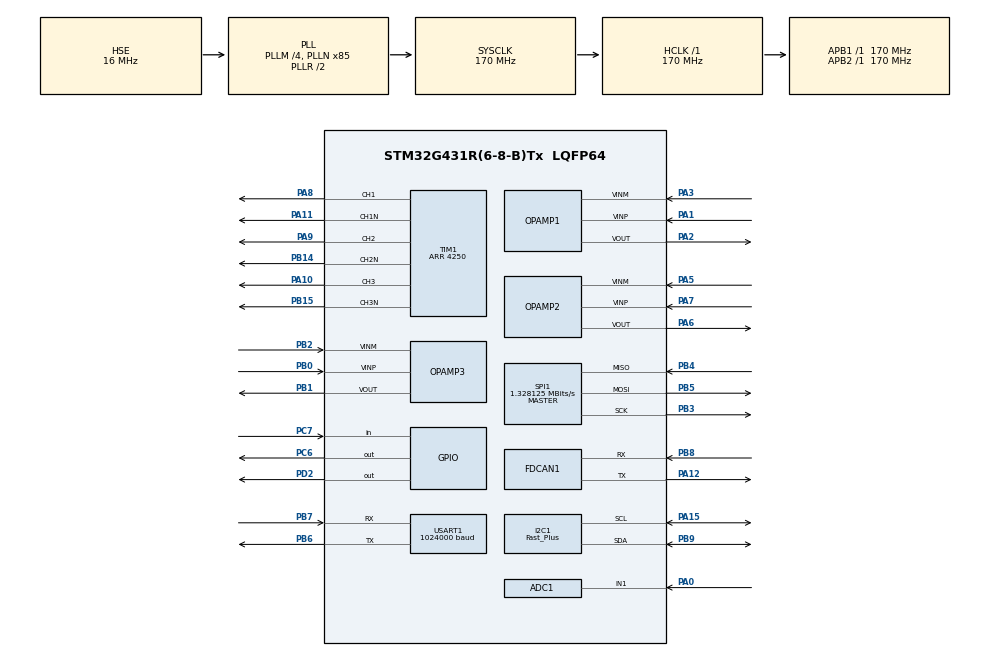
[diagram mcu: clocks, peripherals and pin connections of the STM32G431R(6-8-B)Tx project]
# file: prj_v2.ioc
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ADC1.Channel-0\#ChannelRegularConversion=ADC_CHANNEL_3
ADC1.Channel-1\#ChannelRegularConversion=ADC_CHANNEL_12
ADC1.ClockPrescaler=ADC_CLOCK_ASYNC_DIV2
ADC1.DMAContinuousRequests=ENABLE
ADC1.EOCSelection=ADC_EOC_SEQ_CONV
ADC1.ExternalTrigConv=ADC_EXTERNALTRIG_T1_TRGO
ADC1.NbrOfConversion=2
ADC1.NbrOfConversionFlag=1
ADC1.OffsetNumber-1\#ChannelRegularConversion=ADC_OFFSET_NONE
ADC1.Rank-1\#ChannelRegularConversion=2
ADC1.SamplingTime-0\#ChannelRegularConversion=ADC_SAMPLETIME_12CYCLES_5
ADC1.SamplingTime-1\#ChannelRegularConversion=ADC_SAMPLETIME_12CYCLES_5
ADC1.master=1
ADC2.Channel-0\#ChannelRegularConversion=ADC_CHANNEL_3
ADC2.ClockPrescaler=ADC_CLOCK_ASYNC_DIV2
ADC2.DMAContinuousRequests=ENABLE
ADC2.EOCSelection=ADC_EOC_SEQ_CONV
ADC2.EnableInjectedConversion=DISABLE
ADC2.ExternalTrigConv=ADC_EXTERNALTRIG_T1_TRGO
ADC2.NbrOfConversion=1
ADC2.NbrOfConversionFlag=1
ADC2.OffsetNumber-0\#ChannelRegularConversion=ADC_OFFSET_NONE
ADC2.Rank-0\#ChannelRegularConversion=1
ADC2.Rank1_Channel=ADC_CHANNEL_3
ADC2.SamplingTime-0\#ChannelRegularConversion=ADC_SAMPLETIME_12CYCLES_5
DAC1.DAC_Channel-DAC_OUT2_Int=DAC_CHANNEL_2
Dma.ADC1.2.Direction=DMA_PERIPH_TO_MEMORY
Dma.ADC1.2.EventEnable=DISABLE
Dma.ADC1.2.Instance=DMA1_Channel3
Dma.ADC1.2.MemDataAlignment=DMA_MDATAALIGN_HALFWORD
Dma.ADC1.2.MemInc=DMA_MINC_ENABLE
Dma.ADC1.2.Mode=DMA_CIRCULAR
Dma.ADC1.2.PeriphDataAlignment=DMA_PDATAALIGN_HALFWORD
Dma.ADC1.2.PeriphInc=DMA_PINC_DISABLE
Dma.ADC1.2.Polarity=HAL_DMAMUX_REQ_GEN_RISING
Dma.ADC1.2.Priority=DMA_PRIORITY_LOW
Dma.ADC1.2.RequestNumber=1
Dma.ADC1.2.SignalID=NONE
Dma.ADC1.2.SyncEnable=DISABLE
Dma.ADC1.2.SyncPolarity=HAL_DMAMUX_SYNC_NO_EVENT
Dma.ADC1.2.SyncRequestNumber=1
Dma.ADC1.2.SyncSignalID=NONE
Dma.ADC2.3.Direction=DMA_PERIPH_TO_MEMORY
Dma.ADC2.3.EventEnable=DISABLE
Dma.ADC2.3.Instance=DMA1_Channel4
Dma.ADC2.3.MemDataAlignment=DMA_MDATAALIGN_HALFWORD
Dma.ADC2.3.MemInc=DMA_MINC_ENABLE
Dma.ADC2.3.Mode=DMA_CIRCULAR
Dma.ADC2.3.PeriphDataAlignment=DMA_PDATAALIGN_HALFWORD
Dma.ADC2.3.PeriphInc=DMA_PINC_DISABLE
Dma.ADC2.3.Polarity=HAL_DMAMUX_REQ_GEN_RISING
Dma.ADC2.3.Priority=DMA_PRIORITY_LOW
Dma.ADC2.3.RequestNumber=1
Dma.ADC2.3.SignalID=NONE
Dma.ADC2.3.SyncEnable=DISABLE
Dma.ADC2.3.SyncPolarity=HAL_DMAMUX_SYNC_NO_EVENT
Dma.ADC2.3.SyncRequestNumber=1
Dma.ADC2.3.SyncSignalID=NONE
Dma.I2C1_RX.4.Direction=DMA_PERIPH_TO_MEMORY
Dma.I2C1_RX.4.EventEnable=DISABLE
Dma.I2C1_RX.4.Instance=DMA1_Channel5
Dma.I2C1_RX.4.MemDataAlignment=DMA_MDATAALIGN_BYTE
Dma.I2C1_RX.4.MemInc=DMA_MINC_ENABLE
Dma.I2C1_RX.4.Mode=DMA_NORMAL
Dma.I2C1_RX.4.PeriphDataAlignment=DMA_PDATAALIGN_BYTE
Dma.I2C1_RX.4.PeriphInc=DMA_PINC_DISABLE
Dma.I2C1_RX.4.Polarity=HAL_DMAMUX_REQ_GEN_RISING
Dma.I2C1_RX.4.Priority=DMA_PRIORITY_LOW
Dma.I2C1_RX.4.RequestNumber=1
Dma.I2C1_RX.4.SignalID=NONE
Dma.I2C1_RX.4.SyncEnable=DISABLE
Dma.I2C1_RX.4.SyncPolarity=HAL_DMAMUX_SYNC_NO_EVENT
Dma.I2C1_RX.4.SyncRequestNumber=1
Dma.I2C1_RX.4.SyncSignalID=NONE
Dma.Request0=USART1_TX
Dma.Request1=USART1_RX
Dma.Request2=ADC1
Dma.Request3=ADC2
Dma.Request4=I2C1_RX
Dma.USART1_RX.1.Direction=DMA_PERIPH_TO_MEMORY
Dma.USART1_RX.1.EventEnable=DISABLE
Dma.USART1_RX.1.Instance=DMA1_Channel2
Dma.USART1_RX.1.MemDataAlignment=DMA_MDATAALIGN_BYTE
Dma.USART1_RX.1.MemInc=DMA_MINC_ENABLE
Dma.USART1_RX.1.Mode=DMA_CIRCULAR
Dma.USART1_RX.1.PeriphDataAlignment=DMA_PDATAALIGN_BYTE
Dma.USART1_RX.1.PeriphInc=DMA_PINC_DISABLE
Dma.USART1_RX.1.Polarity=HAL_DMAMUX_REQ_GEN_RISING
Dma.USART1_RX.1.Priority=DMA_PRIORITY_LOW
Dma.USART1_RX.1.RequestNumber=1
Dma.USART1_RX.1.SignalID=NONE
Dma.USART1_RX.1.SyncEnable=DISABLE
Dma.USART1_RX.1.SyncPolarity=HAL_DMAMUX_SYNC_NO_EVENT
Dma.USART1_RX.1.SyncRequestNumber=1
Dma.USART1_RX.1.SyncSignalID=NONE
Dma.USART1_TX.0.Direction=DMA_MEMORY_TO_PERIPH
Dma.USART1_TX.0.EventEnable=DISABLE
Dma.USART1_TX.0.Instance=DMA1_Channel1
Dma.USART1_TX.0.MemDataAlignment=DMA_MDATAALIGN_BYTE
Dma.USART1_TX.0.MemInc=DMA_MINC_ENABLE
Dma.USART1_TX.0.Mode=DMA_NORMAL
Dma.USART1_TX.0.PeriphDataAlignment=DMA_PDATAALIGN_BYTE
Dma.USART1_TX.0.PeriphInc=DMA_PINC_DISABLE
Dma.USART1_TX.0.Polarity=HAL_DMAMUX_REQ_GEN_RISING
Dma.USART1_TX.0.Priority=DMA_PRIORITY_LOW
Dma.USART1_TX.0.RequestNumber=1
Dma.USART1_TX.0.SignalID=NONE
Dma.USART1_TX.0.SyncEnable=DISABLE
Dma.USART1_TX.0.SyncPolarity=HAL_DMAMUX_SYNC_NO_EVENT
Dma.USART1_TX.0.SyncRequestNumber=1
Dma.USART1_TX.0.SyncSignalID=NONE
I2C1.CustomTiming=Disabled
I2C1.I2C_Speed_Mode=I2C_Fast_Plus
I2C1.Timing=0x00802172
Mcu.Family=STM32G4
Mcu.Name=STM32G431R(6-8-B)Tx
Mcu.Package=LQFP64
NVIC.DMA1_Channel1_IRQn=true\:3\:0\:true\:false\:true\:false\:true
NVIC.DMA1_Channel2_IRQn=true\:3\:0\:true\:false\:true\:false\:true
NVIC.DMA1_Channel3_IRQn=true\:1\:0\:true\:false\:true\:false\:true
NVIC.DMA1_Channel4_IRQn=true\:1\:0\:true\:false\:true\:false\:true
NVIC.DMA1_Channel5_IRQn=true\:2\:0\:true\:false\:true\:false\:true
NVIC.I2C1_EV_IRQn=true\:4\:0\:true\:false\:true\:true\:true
NVIC.PriorityGroup=NVIC_PRIORITYGROUP_3
NVIC.TIM1_BRK_TIM15_IRQn=true\:2\:0\:true\:false\:true\:true\:true
NVIC.TIM1_UP_TIM16_IRQn=true\:3\:1\:true\:false\:true\:true\:true
NVIC.USART1_IRQn=true\:4\:0\:true\:false\:true\:true\:true
OPAMP1.PgaGain=OPAMP_PGA_GAIN_32_OR_MINUS_31
OPAMP2.PgaGain=OPAMP_PGA_GAIN_32_OR_MINUS_31
OPAMP3.PgaGain=OPAMP_PGA_GAIN_32_OR_MINUS_31
PA0.Mode=IN1-Single-Ended
PA0.Signal=ADC1_IN1
PA1.Signal=SharedAnalog_PA1
PA10.Signal=S_TIM1_CH3
PA11.Mode=PWM Generation1 CH1 CH1N
PA11.Signal=TIM1_CH1N
PA12.Mode=FDCANFD
PA12.Signal=FDCAN1_TX
PA13.Signal=SYS_JTMS-SWDIO
PA14.Signal=SYS_JTCK-SWCLK
PA15.GPIO_Mode=GPIO_MODE_AF_OD
PA15.GPIO_PuPdOD=GPIO_PULLUP
PA15.GPIO_Speed=GPIO_SPEED_FREQ_LOW
PA15.Mode=I2C
PA15.Signal=I2C1_SCL
PA2.Signal=SharedAnalog_PA2
PA3.Mode=PGA Connected-INVERTINGINPUT_IO0_BIAS
PA3.Signal=OPAMP1_VINM
PA5.Mode=PGA Connected-INVERTINGINPUT_IO0_BIAS
PA5.Signal=OPAMP2_VINM
PA6.Signal=SharedAnalog_PA6
PA7.Signal=SharedAnalog_PA7
PA8.Signal=S_TIM1_CH1
PA9.Signal=S_TIM1_CH2
PB0.Signal=SharedAnalog_PB0
PB1.Signal=SharedAnalog_PB1
PB12.Signal=ADC1_IN11
PB14.Mode=PWM Generation2 CH2 CH2N
PB14.Signal=TIM1_CH2N
PB15.Mode=PWM Generation3 CH3 CH3N
PB15.Signal=TIM1_CH3N
PB2.Mode=PGA Connected-INVERTINGINPUT_IO0_BIAS
PB2.Signal=OPAMP3_VINM
PB3.Mode=Full_Duplex_Master
PB3.Signal=SPI1_SCK
PB4.Mode=Full_Duplex_Master
PB4.Signal=SPI1_MISO
PB5.Mode=Full_Duplex_Master
PB5.Signal=SPI1_MOSI
PB6.Mode=Asynchronous
PB6.Signal=USART1_TX
PB7.Mode=Asynchronous
PB7.Signal=USART1_RX
PB8-BOOT0.Mode=FDCANFD
PB8-BOOT0.Signal=FDCAN1_RX
PB9.GPIO_FM9=__NULL
PB9.GPIO_Mode=GPIO_MODE_AF_OD
PB9.GPIO_PuPdOD=GPIO_PULLUP
PB9.GPIO_Speed=GPIO_SPEED_FREQ_LOW
PB9.Mode=I2C
PB9.Signal=I2C1_SDA
PC6.Signal=GPIO_Output
PC7.Signal=GPIO_Input
PD2.Signal=GPIO_Output
PF0-OSC_IN.Mode=HSE-External-Oscillator
PF0-OSC_IN.Signal=RCC_OSC_IN
PF1-OSC_OUT.Mode=HSE-External-Oscillator
PF1-OSC_OUT.Signal=RCC_OSC_OUT
ProjectManager.HeapSize=0x200
ProjectManager.StackSize=0x400
ProjectManager.TargetToolchain=MDK-ARM V5
RCC.ADC12CLockSelection=RCC_ADC12CLKSOURCE_PLL
RCC.ADC12Freq_Value=42500000
RCC.AHBFreq_Value=170000000
RCC.APB1Freq_Value=170000000
RCC.APB1TimFreq_Value=170000000
RCC.APB2Freq_Value=170000000
RCC.APB2TimFreq_Value=170000000
RCC.CortexFreq_Value=170000000
RCC.EXTERNAL_CLOCK_VALUE=12288000
RCC.HCLKFreq_Value=170000000
RCC.HSE_VALUE=16000000
RCC.HSI48_VALUE=48000000
RCC.HSI_VALUE=16000000
RCC.LSE_VALUE=32768
RCC.PLLM=RCC_PLLM_DIV4
RCC.PLLN=85
RCC.PLLP=RCC_PLLP_DIV8
RCC.PLLSourceVirtual=RCC_PLLSOURCE_HSE
RCC.SYSCLKFreq_VALUE=170000000
RCC.SYSCLKSource=RCC_SYSCLKSOURCE_PLLCLK
RCC.USBFreq_Value=170000000
RCC.VCOOutputFreq_Value=340000000
SH.S_TIM1_CH1.0=TIM1_CH1,PWM Generation1 CH1 CH1N
SH.S_TIM1_CH2.0=TIM1_CH2,PWM Generation2 CH2 CH2N
SH.S_TIM1_CH3.0=TIM1_CH3,PWM Generation3 CH3 CH3N
SH.SharedAnalog_PA1.0=OPAMP1_VINP,PGA Connected-INVERTINGINPUT_IO0_BIAS
SH.SharedAnalog_PA1.1=COMP1_INP,INP
SH.SharedAnalog_PA2.0=OPAMP1_VOUT,PGA Connected-INVERTINGINPUT_IO0_BIAS
SH.SharedAnalog_PA2.1=ADC1_IN3,IN3-Single-Ended
SH.SharedAnalog_PA6.0=OPAMP2_VOUT,PGA Connected-INVERTINGINPUT_IO0_BIAS
SH.SharedAnalog_PA6.1=ADC2_IN3,IN3-Single-Ended
SH.SharedAnalog_PA7.0=OPAMP2_VINP,PGA Connected-INVERTINGINPUT_IO0_BIAS
SH.SharedAnalog_PA7.1=COMP2_INP,INP
SH.SharedAnalog_PB0.0=OPAMP3_VINP,PGA Connected-INVERTINGINPUT_IO0_BIAS
SH.SharedAnalog_PB0.1=COMP4_INP,INP
SH.SharedAnalog_PB1.0=OPAMP3_VOUT,PGA Connected-INVERTINGINPUT_IO0_BIAS
SH.SharedAnalog_PB1.1=ADC1_IN12,IN12-Single-Ended
SPI1.BaudRatePrescaler=SPI_BAUDRATEPRESCALER_128
SPI1.CalculateBaudRate=1.328125 MBits/s
SPI1.Direction=SPI_DIRECTION_2LINES
SPI1.Mode=SPI_MODE_MASTER
SPI1.VirtualType=VM_MASTER
TIM1.Break2Filter=9
TIM1.Channel-PWM\ Generation1\ CH1\ CH1N=TIM_CHANNEL_1
TIM1.Channel-PWM\ Generation2\ CH2\ CH2N=TIM_CHANNEL_2
TIM1.Channel-PWM\ Generation3\ CH3\ CH3N=TIM_CHANNEL_3
TIM1.Channel-PWM\ Generation4\ No\ Output=TIM_CHANNEL_4
TIM1.ClockDivision=TIM_CLOCKDIVISION_DIV1
TIM1.CounterMode=TIM_COUNTERMODE_CENTERALIGNED1
TIM1.DeadTime=200
TIM1.LockLevel=TIM_LOCKLEVEL_2
TIM1.OCMode_PWM-PWM\ Generation4\ No\ Output=TIM_OCMODE_PWM2
TIM1.PeriodNoDither=4250
TIM1.SourceBRK2COMP1=TIM_BREAKINPUTSOURCE_ENABLE
TIM1.SourceBRK2COMP2=TIM_BREAKINPUTSOURCE_ENABLE
TIM1.SourceBRK2COMP4=TIM_BREAKINPUTSOURCE_ENABLE
TIM1.TIM_MasterOutputTrigger=TIM_TRGO_OC4REF
TIM2.PeriodNoDither=0xffffffff
USART1.BaudRate=1024000
USART1.VirtualMode-Asynchronous=VM_ASYNC
USART1.WordLength=WORDLENGTH_8B
VP_COMP1_VS_VREFINT14.Mode=VREFINT_14
VP_COMP2_VS_VREFINT14.Mode=VREFINT_14
VP_COMP4_VS_VREFINT14.Mode=VREFINT_14
VP_CORDIC_VS_CORDIC.Mode=CORDIC_Activate
VP_DAC1_VS_DACI1.Mode=DAC_OUT1_Int
VP_DAC1_VS_DACI2.Mode=DAC_OUT2_Int
VP_SYS_VS_DBSignals.Mode=DisableDeadBatterySignals
VP_TIM1_VS_no_output4.Mode=PWM Generation4 No Output
VP_TIM2_VS_ClockSourceINT.Mode=Internal
board=custom

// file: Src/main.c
/* USER CODE BEGIN Header */
/**
  ******************************************************************************
  * @file           : main.c
  * @brief          : Main program body
  ******************************************************************************
  * @attention
  *
  * <h2><center>&copy; Copyright (c) 2020 STMicroelectronics.
  * All rights reserved.</center></h2>
  *
  * This software component is licensed by ST under BSD 3-Clause license,
  * the "License"; You may not use this file except in compliance with the
  * License. You may obtain a copy of the License at:
  *                        opensource.org/licenses/BSD-3-Clause
  *
  ******************************************************************************
  */
/* USER CODE END Header */

#include "main.h"

/* USER CODE BEGIN Includes */
#include <stdio.h>
#include <math.h>
#include "control_functions.h"
/* USER CODE END Includes */

ADC_HandleTypeDef hadc1;
ADC_HandleTypeDef hadc2;
DMA_HandleTypeDef hdma_adc1;
DMA_HandleTypeDef hdma_adc2;

COMP_HandleTypeDef hcomp1;
COMP_HandleTypeDef hcomp2;
COMP_HandleTypeDef hcomp4;

DAC_HandleTypeDef hdac1;

FDCAN_HandleTypeDef hfdcan1;

I2C_HandleTypeDef hi2c1;
DMA_HandleTypeDef hdma_i2c1_rx;

OPAMP_HandleTypeDef hopamp1;
OPAMP_HandleTypeDef hopamp2;
OPAMP_HandleTypeDef hopamp3;

SPI_HandleTypeDef hspi1;

TIM_HandleTypeDef htim1;
TIM_HandleTypeDef htim2;

UART_HandleTypeDef huart1;
DMA_HandleTypeDef hdma_usart1_tx;
DMA_HandleTypeDef hdma_usart1_rx;

void SystemClock_Config(void);
static void MX_GPIO_Init(void);
static void MX_DMA_Init(void);
static void MX_ADC1_Init(void);
static void MX_ADC2_Init(void);
static void MX_COMP1_Init(void);
static void MX_COMP2_Init(void);
static void MX_COMP4_Init(void);
static void MX_FDCAN1_Init(void);
static void MX_I2C1_Init(void);
static void MX_OPAMP1_Init(void);
static void MX_OPAMP2_Init(void);
static void MX_OPAMP3_Init(void);
static void MX_SPI1_Init(void);
static void MX_TIM1_Init(void);
static void MX_USART1_UART_Init(void);
static void MX_DAC1_Init(void);
static void MX_TIM2_Init(void);
static void MX_CORDIC_Init(void);
/* USER CODE BEGIN PFP */
#ifdef __GNUC__
/* With GCC, small printf (option LD Linker->Libraries->Small printf
   set to 'Yes') calls __io_putchar() */
#define PUTCHAR_PROTOTYPE int __io_putchar(int ch)
#else
#define PUTCHAR_PROTOTYPE int fputc(int ch, FILE *f)
#endif /* __GNUC__ */
/* USER CODE END PFP */

int main(void)
{

  /* MCU Configuration--------------------------------------------------------*/

  /* Reset of all peripherals, Initializes the Flash interface and the Systick. */
  HAL_Init();

  /* Configure the system clock */
  SystemClock_Config();

  /* Initialize all configured peripherals */
  MX_GPIO_Init();
  MX_DMA_Init();
  MX_ADC1_Init();
  MX_ADC2_Init();
  MX_COMP1_Init();
  MX_COMP2_Init();
  MX_COMP4_Init();
  MX_FDCAN1_Init();
  MX_I2C1_Init();
  MX_OPAMP1_Init();
  MX_OPAMP2_Init();
  MX_OPAMP3_Init();
  MX_SPI1_Init();
  MX_TIM1_Init();
  MX_USART1_UART_Init();
  MX_DAC1_Init();
  MX_TIM2_Init();
  MX_CORDIC_Init();
  /* USER CODE BEGIN 2 */
    initControl();

  /* USER CODE END 2 */

  /* Infinite loop */
  /* USER CODE BEGIN WHILE */
  while (1)
  {
	updateControl();
    /* USER CODE END WHILE */

  }
}

void SystemClock_Config(void)
{
  RCC_OscInitTypeDef RCC_OscInitStruct = {0};
  RCC_ClkInitTypeDef RCC_ClkInitStruct = {0};
  RCC_PeriphCLKInitTypeDef PeriphClkInit = {0};

  /** Configure the main internal regulator output voltage
  */
  HAL_PWREx_ControlVoltageScaling(PWR_REGULATOR_VOLTAGE_SCALE1_BOOST);
  /** Initializes the CPU, AHB and APB busses clocks
  */
  RCC_OscInitStruct.OscillatorType = RCC_OSCILLATORTYPE_HSE;
  RCC_OscInitStruct.HSEState = RCC_HSE_ON;
  RCC_OscInitStruct.PLL.PLLState = RCC_PLL_ON;
  RCC_OscInitStruct.PLL.PLLSource = RCC_PLLSOURCE_HSE;
  RCC_OscInitStruct.PLL.PLLM = RCC_PLLM_DIV4;
  RCC_OscInitStruct.PLL.PLLN = 85;
  RCC_OscInitStruct.PLL.PLLP = RCC_PLLP_DIV8;
  RCC_OscInitStruct.PLL.PLLQ = RCC_PLLQ_DIV2;
  RCC_OscInitStruct.PLL.PLLR = RCC_PLLR_DIV2;
  if (HAL_RCC_OscConfig(&RCC_OscInitStruct) != HAL_OK)
  {
    Error_Handler();
  }
  /** Initializes the CPU, AHB and APB busses clocks
  */
  RCC_ClkInitStruct.ClockType = RCC_CLOCKTYPE_HCLK|RCC_CLOCKTYPE_SYSCLK
                              |RCC_CLOCKTYPE_PCLK1|RCC_CLOCKTYPE_PCLK2;
  RCC_ClkInitStruct.SYSCLKSource = RCC_SYSCLKSOURCE_PLLCLK;
  RCC_ClkInitStruct.AHBCLKDivider = RCC_SYSCLK_DIV1;
  RCC_ClkInitStruct.APB1CLKDivider = RCC_HCLK_DIV1;
  RCC_ClkInitStruct.APB2CLKDivider = RCC_HCLK_DIV1;

  if (HAL_RCC_ClockConfig(&RCC_ClkInitStruct, FLASH_LATENCY_8) != HAL_OK)
  {
    Error_Handler();
  }
  /** Initializes the peripherals clocks
  */
  PeriphClkInit.PeriphClockSelection = RCC_PERIPHCLK_USART1|RCC_PERIPHCLK_I2C1
                              |RCC_PERIPHCLK_ADC12|RCC_PERIPHCLK_FDCAN;
  PeriphClkInit.Usart1ClockSelection = RCC_USART1CLKSOURCE_PCLK2;
  PeriphClkInit.I2c1ClockSelection = RCC_I2C1CLKSOURCE_PCLK1;
  PeriphClkInit.FdcanClockSelection = RCC_FDCANCLKSOURCE_PCLK1;
  PeriphClkInit.Adc12ClockSelection = RCC_ADC12CLKSOURCE_PLL;
  if (HAL_RCCEx_PeriphCLKConfig(&PeriphClkInit) != HAL_OK)
  {
    Error_Handler();
  }
}

static void MX_ADC1_Init(void)
{

  ADC_MultiModeTypeDef multimode = {0};
  ADC_ChannelConfTypeDef sConfig = {0};

  /** Common config
  */
  hadc1.Instance = ADC1;
  hadc1.Init.ClockPrescaler = ADC_CLOCK_ASYNC_DIV2;
  hadc1.Init.Resolution = ADC_RESOLUTION_12B;
  hadc1.Init.DataAlign = ADC_DATAALIGN_RIGHT;
  hadc1.Init.GainCompensation = 0;
  hadc1.Init.ScanConvMode = ADC_SCAN_ENABLE;
  hadc1.Init.EOCSelection = ADC_EOC_SEQ_CONV;
  hadc1.Init.LowPowerAutoWait = DISABLE;
  hadc1.Init.ContinuousConvMode = DISABLE;
  hadc1.Init.NbrOfConversion = 2;
  hadc1.Init.DiscontinuousConvMode = DISABLE;
  hadc1.Init.ExternalTrigConv = ADC_EXTERNALTRIG_T1_TRGO;
  hadc1.Init.ExternalTrigConvEdge = ADC_EXTERNALTRIGCONVEDGE_RISING;
  hadc1.Init.DMAContinuousRequests = ENABLE;
  hadc1.Init.Overrun = ADC_OVR_DATA_PRESERVED;
  hadc1.Init.OversamplingMode = DISABLE;
  if (HAL_ADC_Init(&hadc1) != HAL_OK)
  {
    Error_Handler();
  }
  /** Configure the ADC multi-mode
  */
  multimode.Mode = ADC_MODE_INDEPENDENT;
  if (HAL_ADCEx_MultiModeConfigChannel(&hadc1, &multimode) != HAL_OK)
  {
    Error_Handler();
  }
  /** Configure Regular Channel
  */
  sConfig.Channel = ADC_CHANNEL_3;
  sConfig.Rank = ADC_REGULAR_RANK_1;
  sConfig.SamplingTime = ADC_SAMPLETIME_12CYCLES_5;
  sConfig.SingleDiff = ADC_SINGLE_ENDED;
  sConfig.OffsetNumber = ADC_OFFSET_NONE;
  sConfig.Offset = 0;
  if (HAL_ADC_ConfigChannel(&hadc1, &sConfig) != HAL_OK)
  {
    Error_Handler();
  }
  /** Configure Regular Channel
  */
  sConfig.Channel = ADC_CHANNEL_12;
  sConfig.Rank = ADC_REGULAR_RANK_2;
  if (HAL_ADC_ConfigChannel(&hadc1, &sConfig) != HAL_OK)
  {
    Error_Handler();
  }

}

static void MX_ADC2_Init(void)
{

  ADC_ChannelConfTypeDef sConfig = {0};

  /** Common config
  */
  hadc2.Instance = ADC2;
  hadc2.Init.ClockPrescaler = ADC_CLOCK_ASYNC_DIV2;
  hadc2.Init.Resolution = ADC_RESOLUTION_12B;
  hadc2.Init.DataAlign = ADC_DATAALIGN_RIGHT;
  hadc2.Init.GainCompensation = 0;
  hadc2.Init.ScanConvMode = ADC_SCAN_DISABLE;
  hadc2.Init.EOCSelection = ADC_EOC_SEQ_CONV;
  hadc2.Init.LowPowerAutoWait = DISABLE;
  hadc2.Init.ContinuousConvMode = DISABLE;
  hadc2.Init.NbrOfConversion = 1;
  hadc2.Init.DiscontinuousConvMode = DISABLE;
  hadc2.Init.ExternalTrigConv = ADC_EXTERNALTRIG_T1_TRGO;
  hadc2.Init.ExternalTrigConvEdge = ADC_EXTERNALTRIGCONVEDGE_RISING;
  hadc2.Init.DMAContinuousRequests = ENABLE;
  hadc2.Init.Overrun = ADC_OVR_DATA_PRESERVED;
  hadc2.Init.OversamplingMode = DISABLE;
  if (HAL_ADC_Init(&hadc2) != HAL_OK)
  {
    Error_Handler();
  }
  /** Configure Regular Channel
  */
  sConfig.Channel = ADC_CHANNEL_3;
  sConfig.Rank = ADC_REGULAR_RANK_1;
  sConfig.SamplingTime = ADC_SAMPLETIME_12CYCLES_5;
  sConfig.SingleDiff = ADC_SINGLE_ENDED;
  sConfig.OffsetNumber = ADC_OFFSET_NONE;
  sConfig.Offset = 0;
  if (HAL_ADC_ConfigChannel(&hadc2, &sConfig) != HAL_OK)
  {
    Error_Handler();
  }

}

static void MX_COMP1_Init(void)
{

  hcomp1.Instance = COMP1;
  hcomp1.Init.InputPlus = COMP_INPUT_PLUS_IO1;
  hcomp1.Init.InputMinus = COMP_INPUT_MINUS_1_4VREFINT;
  hcomp1.Init.OutputPol = COMP_OUTPUTPOL_NONINVERTED;
  hcomp1.Init.Hysteresis = COMP_HYSTERESIS_NONE;
  hcomp1.Init.BlankingSrce = COMP_BLANKINGSRC_NONE;
  hcomp1.Init.TriggerMode = COMP_TRIGGERMODE_NONE;
  if (HAL_COMP_Init(&hcomp1) != HAL_OK)
  {
    Error_Handler();
  }

}

static void MX_COMP2_Init(void)
{

  hcomp2.Instance = COMP2;
  hcomp2.Init.InputPlus = COMP_INPUT_PLUS_IO1;
  hcomp2.Init.InputMinus = COMP_INPUT_MINUS_1_4VREFINT;
  hcomp2.Init.OutputPol = COMP_OUTPUTPOL_NONINVERTED;
  hcomp2.Init.Hysteresis = COMP_HYSTERESIS_NONE;
  hcomp2.Init.BlankingSrce = COMP_BLANKINGSRC_NONE;
  hcomp2.Init.TriggerMode = COMP_TRIGGERMODE_NONE;
  if (HAL_COMP_Init(&hcomp2) != HAL_OK)
  {
    Error_Handler();
  }

}

static void MX_COMP4_Init(void)
{

  hcomp4.Instance = COMP4;
  hcomp4.Init.InputPlus = COMP_INPUT_PLUS_IO1;
  hcomp4.Init.InputMinus = COMP_INPUT_MINUS_1_4VREFINT;
  hcomp4.Init.OutputPol = COMP_OUTPUTPOL_NONINVERTED;
  hcomp4.Init.Hysteresis = COMP_HYSTERESIS_NONE;
  hcomp4.Init.BlankingSrce = COMP_BLANKINGSRC_NONE;
  hcomp4.Init.TriggerMode = COMP_TRIGGERMODE_NONE;
  if (HAL_COMP_Init(&hcomp4) != HAL_OK)
  {
    Error_Handler();
  }

}

static void MX_CORDIC_Init(void)
{

  /* Peripheral clock enable */
  LL_AHB1_GRP1_EnableClock(LL_AHB1_GRP1_PERIPH_CORDIC);

  /* nothing else to be configured */

}

static void MX_DAC1_Init(void)
{

  DAC_ChannelConfTypeDef sConfig = {0};

  /** DAC Initialization
  */
  hdac1.Instance = DAC1;
  if (HAL_DAC_Init(&hdac1) != HAL_OK)
  {
    Error_Handler();
  }
  /** DAC channel OUT1 config
  */
  sConfig.DAC_HighFrequency = DAC_HIGH_FREQUENCY_INTERFACE_MODE_AUTOMATIC;
  sConfig.DAC_DMADoubleDataMode = DISABLE;
  sConfig.DAC_SignedFormat = DISABLE;
  sConfig.DAC_SampleAndHold = DAC_SAMPLEANDHOLD_DISABLE;
  sConfig.DAC_Trigger = DAC_TRIGGER_NONE;
  sConfig.DAC_Trigger2 = DAC_TRIGGER_NONE;
  sConfig.DAC_OutputBuffer = DAC_OUTPUTBUFFER_DISABLE;
  sConfig.DAC_ConnectOnChipPeripheral = DAC_CHIPCONNECT_ENABLE;
  sConfig.DAC_UserTrimming = DAC_TRIMMING_FACTORY;
  if (HAL_DAC_ConfigChannel(&hdac1, &sConfig, DAC_CHANNEL_1) != HAL_OK)
  {
    Error_Handler();
  }
  /** DAC channel OUT2 config
  */
  sConfig.DAC_ConnectOnChipPeripheral = DAC_CHIPCONNECT_ENABLE;
  if (HAL_DAC_ConfigChannel(&hdac1, &sConfig, DAC_CHANNEL_2) != HAL_OK)
  {
    Error_Handler();
  }

}

static void MX_FDCAN1_Init(void)
{

  hfdcan1.Instance = FDCAN1;
  hfdcan1.Init.ClockDivider = FDCAN_CLOCK_DIV1;
  hfdcan1.Init.FrameFormat = FDCAN_FRAME_FD_NO_BRS;
  hfdcan1.Init.Mode = FDCAN_MODE_NORMAL;
  hfdcan1.Init.AutoRetransmission = DISABLE;
  hfdcan1.Init.TransmitPause = DISABLE;
  hfdcan1.Init.ProtocolException = DISABLE;
  hfdcan1.Init.NominalPrescaler = 1;
  hfdcan1.Init.NominalSyncJumpWidth = 1;
  hfdcan1.Init.NominalTimeSeg1 = 2;
  hfdcan1.Init.NominalTimeSeg2 = 2;
  hfdcan1.Init.DataPrescaler = 1;
  hfdcan1.Init.DataSyncJumpWidth = 1;
  hfdcan1.Init.DataTimeSeg1 = 1;
  hfdcan1.Init.DataTimeSeg2 = 1;
  hfdcan1.Init.StdFiltersNbr = 0;
  hfdcan1.Init.ExtFiltersNbr = 0;
  hfdcan1.Init.TxFifoQueueMode = FDCAN_TX_FIFO_OPERATION;
  if (HAL_FDCAN_Init(&hfdcan1) != HAL_OK)
  {
    Error_Handler();
  }

}

static void MX_I2C1_Init(void)
{

  hi2c1.Instance = I2C1;
  hi2c1.Init.Timing = 0x00802172;
  hi2c1.Init.OwnAddress1 = 0;
  hi2c1.Init.AddressingMode = I2C_ADDRESSINGMODE_7BIT;
  hi2c1.Init.DualAddressMode = I2C_DUALADDRESS_DISABLE;
  hi2c1.Init.OwnAddress2 = 0;
  hi2c1.Init.OwnAddress2Masks = I2C_OA2_NOMASK;
  hi2c1.Init.GeneralCallMode = I2C_GENERALCALL_DISABLE;
  hi2c1.Init.NoStretchMode = I2C_NOSTRETCH_DISABLE;
  if (HAL_I2C_Init(&hi2c1) != HAL_OK)
  {
    Error_Handler();
  }
  /** Configure Analogue filter
  */
  if (HAL_I2CEx_ConfigAnalogFilter(&hi2c1, I2C_ANALOGFILTER_ENABLE) != HAL_OK)
  {
    Error_Handler();
  }
  /** Configure Digital filter
  */
  if (HAL_I2CEx_ConfigDigitalFilter(&hi2c1, 0) != HAL_OK)
  {
    Error_Handler();
  }
  /** I2C Fast mode Plus enable
  */
  __HAL_SYSCFG_FASTMODEPLUS_ENABLE(I2C_FASTMODEPLUS_I2C1);

}

static void MX_OPAMP1_Init(void)
{

  hopamp1.Instance = OPAMP1;
  hopamp1.Init.PowerMode = OPAMP_POWERMODE_NORMAL;
  hopamp1.Init.Mode = OPAMP_PGA_MODE;
  hopamp1.Init.NonInvertingInput = OPAMP_NONINVERTINGINPUT_IO0;
  hopamp1.Init.InternalOutput = DISABLE;
  hopamp1.Init.TimerControlledMuxmode = OPAMP_TIMERCONTROLLEDMUXMODE_DISABLE;
  hopamp1.Init.PgaConnect = OPAMP_PGA_CONNECT_INVERTINGINPUT_IO0_BIAS;
  hopamp1.Init.PgaGain = OPAMP_PGA_GAIN_32_OR_MINUS_31;
  hopamp1.Init.UserTrimming = OPAMP_TRIMMING_FACTORY;
  if (HAL_OPAMP_Init(&hopamp1) != HAL_OK)
  {
    Error_Handler();
  }

}

static void MX_OPAMP2_Init(void)
{

  hopamp2.Instance = OPAMP2;
  hopamp2.Init.PowerMode = OPAMP_POWERMODE_NORMAL;
  hopamp2.Init.Mode = OPAMP_PGA_MODE;
  hopamp2.Init.NonInvertingInput = OPAMP_NONINVERTINGINPUT_IO0;
  hopamp2.Init.InternalOutput = DISABLE;
  hopamp2.Init.TimerControlledMuxmode = OPAMP_TIMERCONTROLLEDMUXMODE_DISABLE;
  hopamp2.Init.PgaConnect = OPAMP_PGA_CONNECT_INVERTINGINPUT_IO0_BIAS;
  hopamp2.Init.PgaGain = OPAMP_PGA_GAIN_32_OR_MINUS_31;
  hopamp2.Init.UserTrimming = OPAMP_TRIMMING_FACTORY;
  if (HAL_OPAMP_Init(&hopamp2) != HAL_OK)
  {
    Error_Handler();
  }

}

static void MX_OPAMP3_Init(void)
{

  hopamp3.Instance = OPAMP3;
  hopamp3.Init.PowerMode = OPAMP_POWERMODE_NORMAL;
  hopamp3.Init.Mode = OPAMP_PGA_MODE;
  hopamp3.Init.NonInvertingInput = OPAMP_NONINVERTINGINPUT_IO0;
  hopamp3.Init.InternalOutput = DISABLE;
  hopamp3.Init.TimerControlledMuxmode = OPAMP_TIMERCONTROLLEDMUXMODE_DISABLE;
  hopamp3.Init.PgaConnect = OPAMP_PGA_CONNECT_INVERTINGINPUT_IO0_BIAS;
  hopamp3.Init.PgaGain = OPAMP_PGA_GAIN_32_OR_MINUS_31;
  hopamp3.Init.UserTrimming = OPAMP_TRIMMING_FACTORY;
  if (HAL_OPAMP_Init(&hopamp3) != HAL_OK)
  {
    Error_Handler();
  }

}

static void MX_SPI1_Init(void)
{

  /* SPI1 parameter configuration*/
  hspi1.Instance = SPI1;
  hspi1.Init.Mode = SPI_MODE_MASTER;
  hspi1.Init.Direction = SPI_DIRECTION_2LINES;
  hspi1.Init.DataSize = SPI_DATASIZE_4BIT;
  hspi1.Init.CLKPolarity = SPI_POLARITY_LOW;
  hspi1.Init.CLKPhase = SPI_PHASE_1EDGE;
  hspi1.Init.NSS = SPI_NSS_SOFT;
  hspi1.Init.BaudRatePrescaler = SPI_BAUDRATEPRESCALER_128;
  hspi1.Init.FirstBit = SPI_FIRSTBIT_MSB;
  hspi1.Init.TIMode = SPI_TIMODE_DISABLE;
  hspi1.Init.CRCCalculation = SPI_CRCCALCULATION_DISABLE;
  hspi1.Init.CRCPolynomial = 7;
  hspi1.Init.CRCLength = SPI_CRC_LENGTH_DATASIZE;
  hspi1.Init.NSSPMode = SPI_NSS_PULSE_ENABLE;
  if (HAL_SPI_Init(&hspi1) != HAL_OK)
  {
    Error_Handler();
  }

}

static void MX_TIM1_Init(void)
{

  TIM_MasterConfigTypeDef sMasterConfig = {0};
  TIMEx_BreakInputConfigTypeDef sBreakInputConfig = {0};
  TIM_OC_InitTypeDef sConfigOC = {0};
  TIM_BreakDeadTimeConfigTypeDef sBreakDeadTimeConfig = {0};

  htim1.Instance = TIM1;
  htim1.Init.Prescaler = 0;
  htim1.Init.CounterMode = TIM_COUNTERMODE_CENTERALIGNED1;
  htim1.Init.Period = 4250;
  htim1.Init.ClockDivision = TIM_CLOCKDIVISION_DIV1;
  htim1.Init.RepetitionCounter = 0;
  htim1.Init.AutoReloadPreload = TIM_AUTORELOAD_PRELOAD_DISABLE;
  if (HAL_TIM_PWM_Init(&htim1) != HAL_OK)
  {
    Error_Handler();
  }
  sMasterConfig.MasterOutputTrigger = TIM_TRGO_OC4REF;
  sMasterConfig.MasterOutputTrigger2 = TIM_TRGO2_RESET;
  sMasterConfig.MasterSlaveMode = TIM_MASTERSLAVEMODE_DISABLE;
  if (HAL_TIMEx_MasterConfigSynchronization(&htim1, &sMasterConfig) != HAL_OK)
  {
    Error_Handler();
  }
  sBreakInputConfig.Source = TIM_BREAKINPUTSOURCE_COMP1;
  sBreakInputConfig.Enable = TIM_BREAKINPUTSOURCE_ENABLE;
  sBreakInputConfig.Polarity = TIM_BREAKINPUTSOURCE_POLARITY_HIGH;
  if (HAL_TIMEx_ConfigBreakInput(&htim1, TIM_BREAKINPUT_BRK2, &sBreakInputConfig) != HAL_OK)
  {
    Error_Handler();
  }
  sBreakInputConfig.Source = TIM_BREAKINPUTSOURCE_COMP2;
  if (HAL_TIMEx_ConfigBreakInput(&htim1, TIM_BREAKINPUT_BRK2, &sBreakInputConfig) != HAL_OK)
  {
    Error_Handler();
  }
  sBreakInputConfig.Source = TIM_BREAKINPUTSOURCE_COMP4;
  if (HAL_TIMEx_ConfigBreakInput(&htim1, TIM_BREAKINPUT_BRK2, &sBreakInputConfig) != HAL_OK)
  {
    Error_Handler();
  }
  sConfigOC.OCMode = TIM_OCMODE_PWM1;
  sConfigOC.Pulse = 0;
  sConfigOC.OCPolarity = TIM_OCPOLARITY_HIGH;
  sConfigOC.OCNPolarity = TIM_OCNPOLARITY_HIGH;
  sConfigOC.OCFastMode = TIM_OCFAST_DISABLE;
  sConfigOC.OCIdleState = TIM_OCIDLESTATE_RESET;
  sConfigOC.OCNIdleState = TIM_OCNIDLESTATE_RESET;
  if (HAL_TIM_PWM_ConfigChannel(&htim1, &sConfigOC, TIM_CHANNEL_1) != HAL_OK)
  {
    Error_Handler();
  }
  sConfigOC.Pulse = 0;
  if (HAL_TIM_PWM_ConfigChannel(&htim1, &sConfigOC, TIM_CHANNEL_2) != HAL_OK)
  {
    Error_Handler();
  }
  sConfigOC.Pulse = 0;
  if (HAL_TIM_PWM_ConfigChannel(&htim1, &sConfigOC, TIM_CHANNEL_3) != HAL_OK)
  {
    Error_Handler();
  }
  sConfigOC.OCMode = TIM_OCMODE_PWM2;
  sConfigOC.Pulse = 0;
  sConfigOC.OCNPolarity = TIM_OCNPOLARITY_HIGH;
  if (HAL_TIM_PWM_ConfigChannel(&htim1, &sConfigOC, TIM_CHANNEL_4) != HAL_OK)
  {
    Error_Handler();
  }
  sBreakDeadTimeConfig.OffStateRunMode = TIM_OSSR_DISABLE;
  sBreakDeadTimeConfig.OffStateIDLEMode = TIM_OSSI_DISABLE;
  sBreakDeadTimeConfig.LockLevel = TIM_LOCKLEVEL_2;
  sBreakDeadTimeConfig.DeadTime = 200;
  sBreakDeadTimeConfig.BreakState = TIM_BREAK_DISABLE;
  sBreakDeadTimeConfig.BreakPolarity = TIM_BREAKPOLARITY_HIGH;
  sBreakDeadTimeConfig.BreakFilter = 0;
  sBreakDeadTimeConfig.BreakAFMode = TIM_BREAK_AFMODE_INPUT;
  sBreakDeadTimeConfig.Break2State = TIM_BREAK2_DISABLE;
  sBreakDeadTimeConfig.Break2Polarity = TIM_BREAK2POLARITY_HIGH;
  sBreakDeadTimeConfig.Break2Filter = 9;
  sBreakDeadTimeConfig.Break2AFMode = TIM_BREAK_AFMODE_INPUT;
  sBreakDeadTimeConfig.AutomaticOutput = TIM_AUTOMATICOUTPUT_DISABLE;
  if (HAL_TIMEx_ConfigBreakDeadTime(&htim1, &sBreakDeadTimeConfig) != HAL_OK)
  {
    Error_Handler();
  }
  HAL_TIM_MspPostInit(&htim1);

}

static void MX_TIM2_Init(void)
{

  TIM_ClockConfigTypeDef sClockSourceConfig = {0};
  TIM_MasterConfigTypeDef sMasterConfig = {0};

  htim2.Instance = TIM2;
  htim2.Init.Prescaler = 0;
  htim2.Init.CounterMode = TIM_COUNTERMODE_UP;
  htim2.Init.Period = 0xffffffff;
  htim2.Init.ClockDivision = TIM_CLOCKDIVISION_DIV1;
  htim2.Init.AutoReloadPreload = TIM_AUTORELOAD_PRELOAD_DISABLE;
  if (HAL_TIM_Base_Init(&htim2) != HAL_OK)
  {
    Error_Handler();
  }
  sClockSourceConfig.ClockSource = TIM_CLOCKSOURCE_INTERNAL;
  if (HAL_TIM_ConfigClockSource(&htim2, &sClockSourceConfig) != HAL_OK)
  {
    Error_Handler();
  }
  sMasterConfig.MasterOutputTrigger = TIM_TRGO_RESET;
  sMasterConfig.MasterSlaveMode = TIM_MASTERSLAVEMODE_DISABLE;
  if (HAL_TIMEx_MasterConfigSynchronization(&htim2, &sMasterConfig) != HAL_OK)
  {
    Error_Handler();
  }

}

static void MX_USART1_UART_Init(void)
{

  huart1.Instance = USART1;
  huart1.Init.BaudRate = 1024000;
  huart1.Init.WordLength = UART_WORDLENGTH_8B;
  huart1.Init.StopBits = UART_STOPBITS_1;
  huart1.Init.Parity = UART_PARITY_NONE;
  huart1.Init.Mode = UART_MODE_TX_RX;
  huart1.Init.HwFlowCtl = UART_HWCONTROL_NONE;
  huart1.Init.OverSampling = UART_OVERSAMPLING_16;
  huart1.Init.OneBitSampling = UART_ONE_BIT_SAMPLE_DISABLE;
  huart1.Init.ClockPrescaler = UART_PRESCALER_DIV1;
  huart1.AdvancedInit.AdvFeatureInit = UART_ADVFEATURE_NO_INIT;
  if (HAL_UART_Init(&huart1) != HAL_OK)
  {
    Error_Handler();
  }
  if (HAL_UARTEx_SetTxFifoThreshold(&huart1, UART_TXFIFO_THRESHOLD_1_8) != HAL_OK)
  {
    Error_Handler();
  }
  if (HAL_UARTEx_SetRxFifoThreshold(&huart1, UART_RXFIFO_THRESHOLD_1_8) != HAL_OK)
  {
    Error_Handler();
  }
  if (HAL_UARTEx_DisableFifoMode(&huart1) != HAL_OK)
  {
    Error_Handler();
  }

}

static void MX_DMA_Init(void)
{

  /* DMA controller clock enable */
  __HAL_RCC_DMAMUX1_CLK_ENABLE();
  __HAL_RCC_DMA1_CLK_ENABLE();

  /* DMA interrupt init */
  /* DMA1_Channel1_IRQn interrupt configuration */
  HAL_NVIC_SetPriority(DMA1_Channel1_IRQn, 3, 0);
  HAL_NVIC_EnableIRQ(DMA1_Channel1_IRQn);
  /* DMA1_Channel2_IRQn interrupt configuration */
  HAL_NVIC_SetPriority(DMA1_Channel2_IRQn, 3, 0);
  HAL_NVIC_EnableIRQ(DMA1_Channel2_IRQn);
  /* DMA1_Channel3_IRQn interrupt configuration */
  HAL_NVIC_SetPriority(DMA1_Channel3_IRQn, 1, 0);
  HAL_NVIC_EnableIRQ(DMA1_Channel3_IRQn);
  /* DMA1_Channel4_IRQn interrupt configuration */
  HAL_NVIC_SetPriority(DMA1_Channel4_IRQn, 1, 0);
  HAL_NVIC_EnableIRQ(DMA1_Channel4_IRQn);
  /* DMA1_Channel5_IRQn interrupt configuration */
  HAL_NVIC_SetPriority(DMA1_Channel5_IRQn, 2, 0);
  HAL_NVIC_EnableIRQ(DMA1_Channel5_IRQn);

}

static void MX_GPIO_Init(void)
{
  GPIO_InitTypeDef GPIO_InitStruct = {0};

  /* GPIO Ports Clock Enable */
  __HAL_RCC_GPIOF_CLK_ENABLE();
  __HAL_RCC_GPIOA_CLK_ENABLE();
  __HAL_RCC_GPIOB_CLK_ENABLE();
  __HAL_RCC_GPIOC_CLK_ENABLE();
  __HAL_RCC_GPIOD_CLK_ENABLE();

  /*Configure GPIO pin Output Level */
  HAL_GPIO_WritePin(GPIOC, GPIO_PIN_6, GPIO_PIN_RESET);

  /*Configure GPIO pin Output Level */
  HAL_GPIO_WritePin(GPIOD, GPIO_PIN_2, GPIO_PIN_RESET);

  /*Configure GPIO pin : PC6 */
  GPIO_InitStruct.Pin = GPIO_PIN_6;
  GPIO_InitStruct.Mode = GPIO_MODE_OUTPUT_PP;
  GPIO_InitStruct.Pull = GPIO_NOPULL;
  GPIO_InitStruct.Speed = GPIO_SPEED_FREQ_LOW;
  HAL_GPIO_Init(GPIOC, &GPIO_InitStruct);

  /*Configure GPIO pin : PC7 */
  GPIO_InitStruct.Pin = GPIO_PIN_7;
  GPIO_InitStruct.Mode = GPIO_MODE_INPUT;
  GPIO_InitStruct.Pull = GPIO_NOPULL;
  HAL_GPIO_Init(GPIOC, &GPIO_InitStruct);

  /*Configure GPIO pin : PD2 */
  GPIO_InitStruct.Pin = GPIO_PIN_2;
  GPIO_InitStruct.Mode = GPIO_MODE_OUTPUT_PP;
  GPIO_InitStruct.Pull = GPIO_NOPULL;
  GPIO_InitStruct.Speed = GPIO_SPEED_FREQ_LOW;
  HAL_GPIO_Init(GPIOD, &GPIO_InitStruct);

}

/* USER CODE BEGIN 4 */
PUTCHAR_PROTOTYPE
{
  /* Place your implementation of fputc here */
  /* e.g. write a character to the LPUART1 and Loop until the end of transmission */
  HAL_UART_Transmit(&huart1, (uint8_t *)&ch, 1, 0xffff);

  return ch;
}
/* USER CODE END 4 */

void Error_Handler(void)
{
}

/************************ (C) COPYRIGHT STMicroelectronics *****END OF FILE****/
